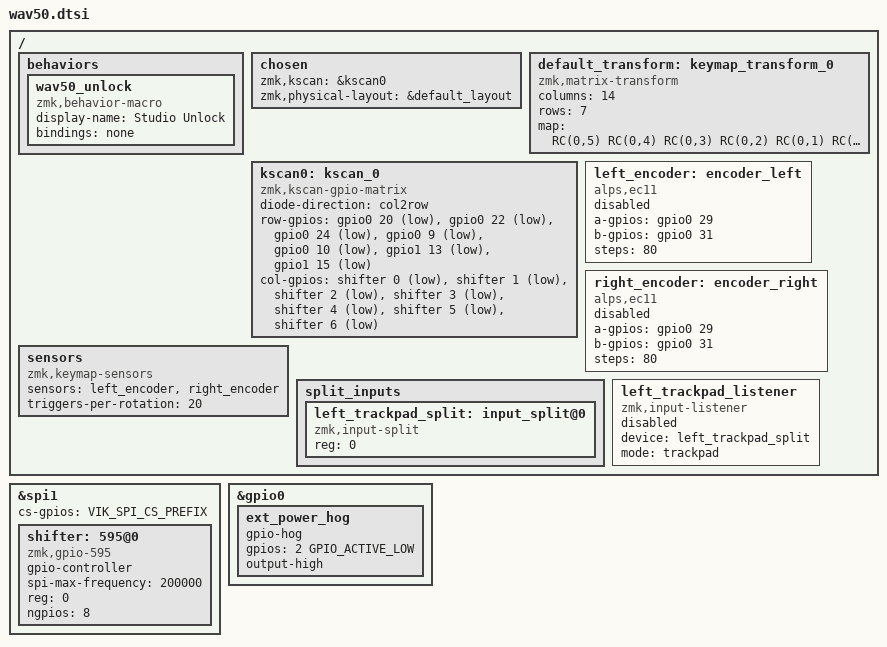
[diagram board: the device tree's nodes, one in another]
#include <behaviors.dtsi>
#include <dt-bindings/zmk/matrix_transform.h>
#include <dt-bindings/zmk/keys.h>
#include "wav50-layouts.dtsi"

// Tell VIK that there is 1 other device on the SPI bus.
// You will need to increase this number if you add another SPI device.
#define VIK_SPI_REG_START 1
// Pulled out to an external variable so VIK can find the SPI bus.
#define VIK_SPI_CS_PREFIX <&gpio0 4 GPIO_ACTIVE_LOW>

&spi1 {
    status = "okay";
    cs-gpios = VIK_SPI_CS_PREFIX;

    shifter: 595@0 {
        compatible = "zmk,gpio-595";
        status = "okay";
        gpio-controller;
        spi-max-frequency = <200000>;
        reg = <0>;
        ngpios = <8>;
        #gpio-cells = <2>;
    };
};

/ {
    behaviors {
        wav50_unlock: wav50_unlock {
            compatible = "zmk,behavior-macro";
            #binding-cells = <0>;
            display-name = "Studio Unlock";
            bindings = <&none>;
        };
    };

    chosen {
        zmk,kscan = &kscan0;
        zmk,physical-layout = &default_layout;
    };

    default_transform: keymap_transform_0 {
        compatible = "zmk,matrix-transform";
        columns = <14>;
        rows = <7>;
        map = <RC(0,5) RC(0,4) RC(0,3) RC(0,2) RC(0,1) RC(0,0) RC(0,12) RC(0,11) RC(0,10) RC(0,9) RC(0,8) RC(0,7) RC(1,5) RC(1,4) RC(1,3) RC(1,2) RC(1,1) RC(1,0) RC(1,12) RC(1,11) RC(1,10) RC(1,9) RC(1,8) RC(1,7) RC(2,4) RC(2,3) RC(2,2) RC(2,1) RC(2,0) RC(3,1) RC(3,1) RC(2,12) RC(2,11) RC(2,10) RC(2,9) RC(2,8) RC(3,3) RC(3,2) RC(3,10) RC(3,9) RC(3,1) RC(3,0) RC(4,0) RC(4,12) RC(3,12) RC(3,11)>;
    };

    kscan0: kscan_0 {
        compatible = "zmk,kscan-gpio-matrix";
        diode-direction = "col2row";

        row-gpios
            = <&gpio0 20 (GPIO_ACTIVE_LOW | GPIO_PULL_UP)>
            , <&gpio0 22 (GPIO_ACTIVE_LOW | GPIO_PULL_UP)>
            , <&gpio0 24 (GPIO_ACTIVE_LOW | GPIO_PULL_UP)>
            , <&gpio0 9  (GPIO_ACTIVE_LOW | GPIO_PULL_UP)>
            , <&gpio0 10 (GPIO_ACTIVE_LOW | GPIO_PULL_UP)>
            , <&gpio1 13 (GPIO_ACTIVE_LOW | GPIO_PULL_UP)>
            , <&gpio1 15 (GPIO_ACTIVE_LOW | GPIO_PULL_UP)>
            ;

        col-gpios
            = <&shifter 0 GPIO_ACTIVE_LOW>
            , <&shifter 1 GPIO_ACTIVE_LOW>
            , <&shifter 2 GPIO_ACTIVE_LOW>
            , <&shifter 3 GPIO_ACTIVE_LOW>
            , <&shifter 4 GPIO_ACTIVE_LOW>
            , <&shifter 5 GPIO_ACTIVE_LOW>
            , <&shifter 6 GPIO_ACTIVE_LOW>
            ;
    };

    left_encoder: encoder_left {
        compatible = "alps,ec11";
        a-gpios = <&gpio0 29 (GPIO_ACTIVE_HIGH | GPIO_PULL_UP)>;
        b-gpios = <&gpio0 31 (GPIO_ACTIVE_HIGH | GPIO_PULL_UP)>;
        steps = <80>;
        status = "disabled";
    };

    right_encoder: encoder_right {
        compatible = "alps,ec11";
        a-gpios = <&gpio0 29 (GPIO_ACTIVE_HIGH | GPIO_PULL_UP)>;
        b-gpios = <&gpio0 31 (GPIO_ACTIVE_HIGH | GPIO_PULL_UP)>;
        steps = <80>;
        status = "disabled";
    };

    sensors: sensors {
        compatible = "zmk,keymap-sensors";
        sensors = <&left_encoder &right_encoder>;
        triggers-per-rotation = <20>;
    };

    split_inputs {
        #address-cells = <1>;
        #size-cells = <0>;

        left_trackpad_split: input_split@0 {
            compatible = "zmk,input-split";
            reg = <0>;
        };
    };

    left_trackpad_listener: left_trackpad_listener {
        compatible = "zmk,input-listener";
        status = "disabled";
        device = <&left_trackpad_split>;
        mode = "trackpad";
    };
};

// Hack to force-drive the LED power pin high, ensuring LED power is off. Ext power is also disabled in the conf file.

&gpio0 {
    ext_power_hog: ext_power_hog {
        gpio-hog;
        gpios = <2 GPIO_ACTIVE_LOW>;
        output-high;
    };
};
